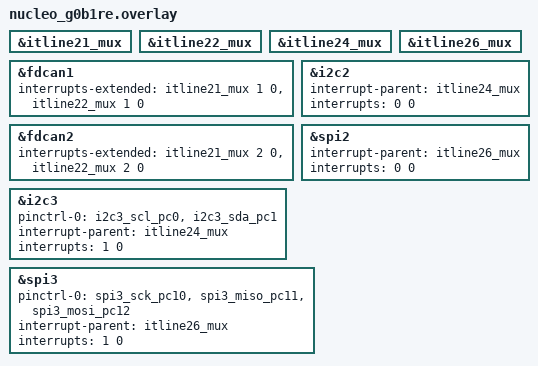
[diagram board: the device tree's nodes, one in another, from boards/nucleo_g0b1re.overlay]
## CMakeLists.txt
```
# SPDX-License-Identifier: Apache-2.0

cmake_minimum_required(VERSION 3.20.0)
find_package(Zephyr REQUIRED HINTS $ENV{ZEPHYR_BASE})
project(stm32_syscfg_itline)
target_sources(app PRIVATE src/main.c)
```

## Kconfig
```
# Private config options for STM32 SYSCFG itline sample app

# Copyright (c) 2024 Etienne Raquin
# SPDX-License-Identifier: Apache-2.0

mainmenu "STM32 SYSCFG itline sample application"

config NUM_IRQS
	default 44

config NUM_2ND_LEVEL_AGGREGATORS
	default 4

config MAX_IRQ_PER_AGGREGATOR
	default 3

config 2ND_LVL_ISR_TBL_OFFSET
	default 32

config 2ND_LVL_INTR_00_OFFSET
	default 21

config 2ND_LVL_INTR_01_OFFSET
	default 22

config 2ND_LVL_INTR_02_OFFSET
	default 24

config 2ND_LVL_INTR_03_OFFSET
	default 26

config SYSCFG_STM32
	default y

config SHARED_INTERRUPTS
	default n

source "Kconfig.zephyr"
```

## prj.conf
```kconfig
CONFIG_ASSERT=y

CONFIG_CAN=y
CONFIG_CAN_STM32_FDCAN=y

CONFIG_I2C=y
CONFIG_I2C_STM32=y
CONFIG_I2C_STM32_INTERRUPT=y

CONFIG_SPI=y
CONFIG_SPI_STM32=y
CONFIG_SPI_STM32_INTERRUPT=y
```

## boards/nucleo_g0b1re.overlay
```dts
/*
 * Copyright (c) 2024 Etienne Raquin
 *
 * SPDX-License-Identifier: Apache-2.0
 */

&itline21_mux {
	status = "okay";
};

&itline22_mux {
	status = "okay";
};

&itline24_mux {
	status = "okay";
};

&itline26_mux {
	status = "okay";
};

&fdcan1 {
	interrupts-extended = <&itline21_mux 1 0>, <&itline22_mux 1 0>;
};

&fdcan2 {
	interrupts-extended = <&itline21_mux 2 0>, <&itline22_mux 2 0>;
};

&i2c2 {
	interrupt-parent = <&itline24_mux>;
	interrupts = <0 0>;
};

&i2c3 {
	pinctrl-0 = <&i2c3_scl_pc0 &i2c3_sda_pc1>;
	pinctrl-names = "default";
	interrupt-parent = <&itline24_mux>;
	interrupts = <1 0>;
	status = "okay";
};

&spi2 {
	interrupt-parent = <&itline26_mux>;
	interrupts = <0 0>;
};

&spi3 {
	pinctrl-0 = <&spi3_sck_pc10 &spi3_miso_pc11 &spi3_mosi_pc12>;
	pinctrl-names = "default";
	interrupt-parent = <&itline26_mux>;
	interrupts = <1 0>;
	status = "okay";
};
```

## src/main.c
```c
/**
 * Copyright (c) 2024, Etienne Raquin
 *
 * SPDX-License-Identifier: Apache-2.0
 */

#include <stdio.h>
#include <zephyr/kernel.h>

#define SLEEP_TIME K_MSEC(1000)

int main(void)
{
	printf("Start\n");

	while (1) {
		printf("Loop it\n");
		k_sleep(SLEEP_TIME);
	}
}
```
